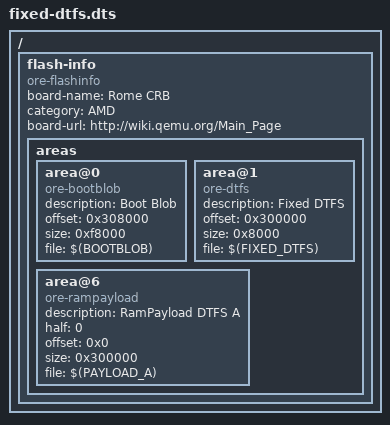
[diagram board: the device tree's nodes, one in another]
/dts-v1/;

/ {
    #address-cells = <1>;
    #size-cells = <1>;

    flash-info {
        compatible = "ore-flashinfo";
        board-name = "Rome CRB";
        category = "AMD";
        board-url = "http://wiki.qemu.org/Main_Page";
        areas {
            area@0 {
                description = "Boot Blob";
                compatible = "ore-bootblob";
                offset = <0x308000>;
                size = <0xf8000>;
                file = "$(BOOTBLOB)";
            };
            area@1 {
                description = "Fixed DTFS";
                compatible = "ore-dtfs";
                offset = <0x300000>;
                size = <0x8000>;
                file = "$(FIXED_DTFS)";
            };
            area@6 {
                description = "RamPayload DTFS A";
                compatible = "ore-rampayload";
                half = <0>;
                offset = <0x0>;
                size = <0x300000>;
                file = "$(PAYLOAD_A)";
            };
        };
    };
};
